# BL602 register map
Vendor: bouffalolab; Series: WiFi BT
Registers are 32-bit, read-write, reset 0x0 unless marked. A register's access mark holds for its fields unless they carry their own. Offsets are from the block's base; [hi:lo] are bit positions; {n}, {i} and the like mark numbered series.

## I2C — I2C control
Base 0x4000A300
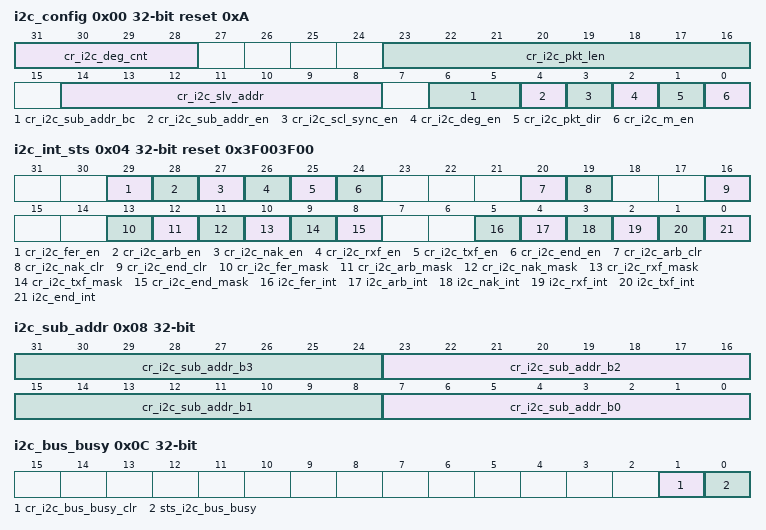
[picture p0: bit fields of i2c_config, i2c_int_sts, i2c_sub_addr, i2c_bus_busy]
0x00 i2c_config reset 0xA
  [31:28] cr_i2c_deg_cnt, [23:16] cr_i2c_pkt_len, [14:8] cr_i2c_slv_addr, [6:5] cr_i2c_sub_addr_bc, [4] cr_i2c_sub_addr_en, [3] cr_i2c_scl_sync_en, [2] cr_i2c_deg_en, [1] cr_i2c_pkt_dir, [0] cr_i2c_m_en
0x04 i2c_int_sts reset 0x3F003F00
  [29] cr_i2c_fer_en, [28] cr_i2c_arb_en, [27] cr_i2c_nak_en, [26] cr_i2c_rxf_en, [25] cr_i2c_txf_en, [24] cr_i2c_end_en, [20] cr_i2c_arb_clr, [19] cr_i2c_nak_clr, [16] cr_i2c_end_clr, [13] cr_i2c_fer_mask, [12] cr_i2c_arb_mask, [11] cr_i2c_nak_mask, [10] cr_i2c_rxf_mask, [9] cr_i2c_txf_mask, [8] cr_i2c_end_mask, [5] i2c_fer_int ro, [4] i2c_arb_int ro, [3] i2c_nak_int ro, [2] i2c_rxf_int ro, [1] i2c_txf_int ro, [0] i2c_end_int ro
0x08 i2c_sub_addr
  [8n+7:8n] cr_i2c_sub_addr_b{n} (n=0..3)
0x0C i2c_bus_busy
  [1] cr_i2c_bus_busy_clr, [0] sts_i2c_bus_busy ro
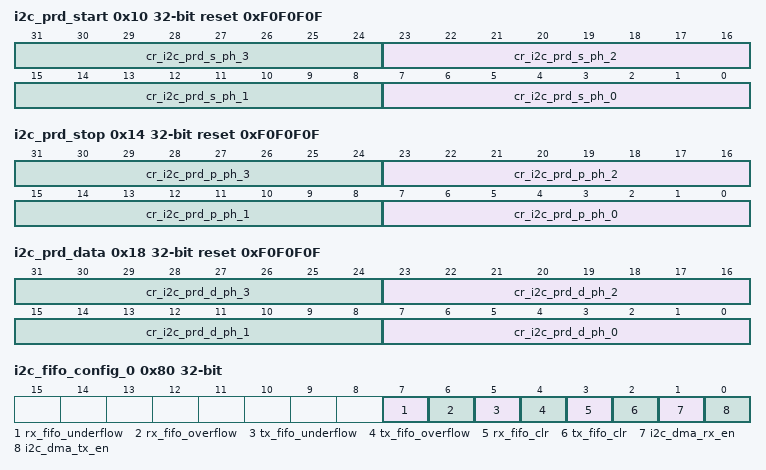
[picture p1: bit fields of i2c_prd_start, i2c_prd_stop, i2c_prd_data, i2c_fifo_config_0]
0x10 i2c_prd_start reset 0xF0F0F0F
  [8n+7:8n] cr_i2c_prd_s_ph_{n} (n=0..3)
0x14 i2c_prd_stop reset 0xF0F0F0F
  [8n+7:8n] cr_i2c_prd_p_ph_{n} (n=0..3)
0x18 i2c_prd_data reset 0xF0F0F0F
  [8n+7:8n] cr_i2c_prd_d_ph_{n} (n=0..3)
0x80 i2c_fifo_config_0
  [7] rx_fifo_underflow ro, [6] rx_fifo_overflow ro, [5] tx_fifo_underflow ro, [4] tx_fifo_overflow ro, [3] rx_fifo_clr, [2] tx_fifo_clr, [1] i2c_dma_rx_en, [0] i2c_dma_tx_en
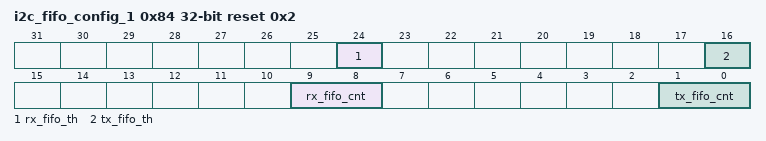
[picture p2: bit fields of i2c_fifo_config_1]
0x84 i2c_fifo_config_1 reset 0x2
  [24] rx_fifo_th, [16] tx_fifo_th, [9:8] rx_fifo_cnt ro, [1:0] tx_fifo_cnt ro
0x88 i2c_fifo_wdata wo
0x8C i2c_fifo_rdata ro

## PWM — Pulse width modulation control
Base 0x4000A400
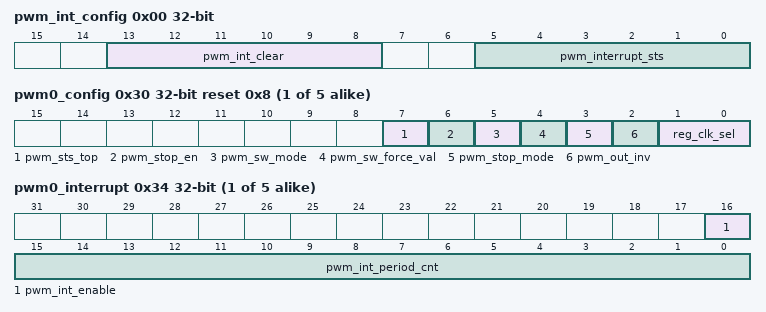
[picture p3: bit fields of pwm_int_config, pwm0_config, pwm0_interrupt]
0x00 pwm_int_config
  [13:8] pwm_int_clear wo, [5:0] pwm_interrupt_sts ro
{0x20+0x20*i} pwm{i}_clkdiv (i=0..4)
  [15:0] pwm_clk_div
{0x24+0x20*i} pwm{i}_thre1 (i=0..4)
  [15:0] pwm_thre1
{0x28+0x20*i} pwm{i}_thre2 (i=0..4)
  [15:0] pwm_thre2
{0x2C+0x20*i} pwm{i}_period (i=0..4)
  [15:0] pwm_period
{0x30+0x20*i} pwm{i}_config reset 0x8 (i=0..4)
  [7] pwm_sts_top ro, [6] pwm_stop_en, [5] pwm_sw_mode, [4] pwm_sw_force_val, [3] pwm_stop_mode, [2] pwm_out_inv, [1:0] reg_clk_sel
{0x34+0x20*i} pwm{i}_interrupt (i=0..4)
  [16] pwm_int_enable, [15:0] pwm_int_period_cnt

## TIMER — Timer control
Base 0x4000A500
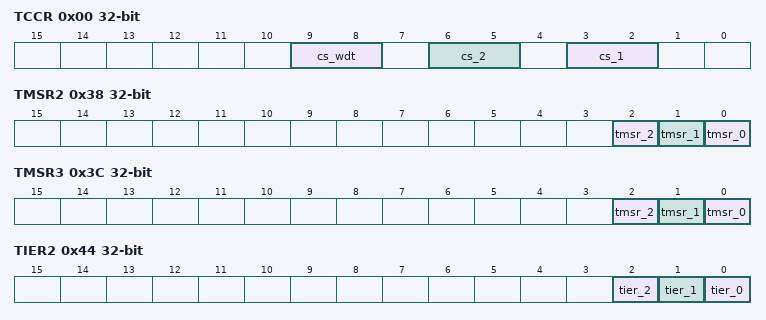
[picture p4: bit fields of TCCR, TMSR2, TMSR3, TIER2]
0x00 TCCR
  [9:8] cs_wdt, [6:5] cs_2, [3:2] cs_1
{0x10+4i} TMR2_{i} reset 0xFFFFFFFF (i=0..2)
  [31:0] tmr
{0x1C+4i} TMR3_{i} reset 0xFFFFFFFF (i=0..2)
  [31:0] tmr
0x2C TCR2 ro
  [31:0] tcr
0x30 TCR3 ro
  [31:0] tcr3_counter
0x38 TMSR2 ro
  [2] tmsr_2, [1] tmsr_1, [0] tmsr_0
0x3C TMSR3 ro
  [2] tmsr_2, [1] tmsr_1, [0] tmsr_0
0x44 TIER2
  [2] tier_2, [1] tier_1, [0] tier_0
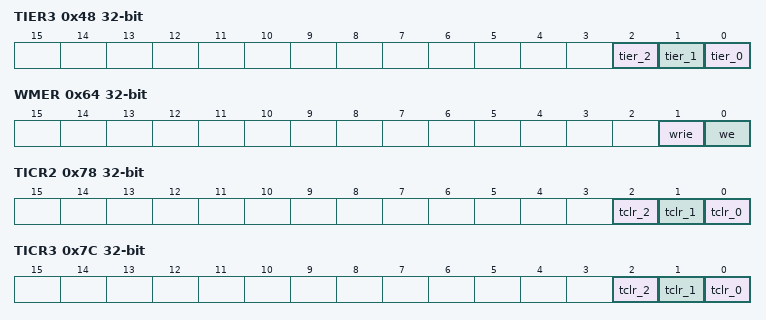
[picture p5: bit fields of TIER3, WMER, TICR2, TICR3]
0x48 TIER3
  [2] tier_2, [1] tier_1, [0] tier_0
0x50 TPLVR2
  [31:0] tplvr
0x54 TPLVR3
  [31:0] tplvr
0x5C TPLCR2
  [1:0] tplcr
0x60 TPLCR3
  [1:0] tplcr
0x64 WMER
  [1] wrie, [0] we
0x68 WMR reset 0xFFFF
  [15:0] wmr
0x6C WVR ro
  [15:0] wvr
0x70 WSR
  [0] wts
0x78 TICR2 wo
  [2] tclr_2, [1] tclr_1, [0] tclr_0
0x7C TICR3 wo
  [2] tclr_2, [1] tclr_1, [0] tclr_0
0x80 WICR wo
  [0] wiclr
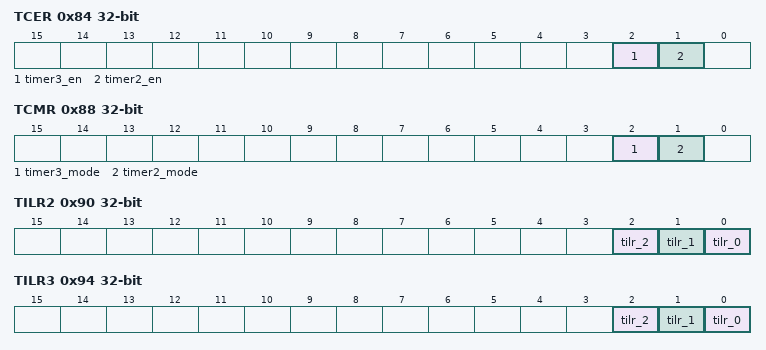
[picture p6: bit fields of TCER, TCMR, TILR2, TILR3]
0x84 TCER
  [2] timer3_en, [1] timer2_en
0x88 TCMR
  [2] timer3_mode, [1] timer2_mode
0x90 TILR2
  [2] tilr_2, [1] tilr_1, [0] tilr_0
0x94 TILR3
  [2] tilr_2, [1] tilr_1, [0] tilr_0
0x98 WCR wo
  [0] wcr
0x9C WFAR wo
  [15:0] wfar
0xA0 WSAR wo
  [15:0] wsar
0xA8 TCVWR2 ro
  [31:0] tcvwr
0xAC TCVWR3 ro
  [31:0] tcvwr
0xB4 TCVSYN2 ro
0xB8 TCVSYN3 ro
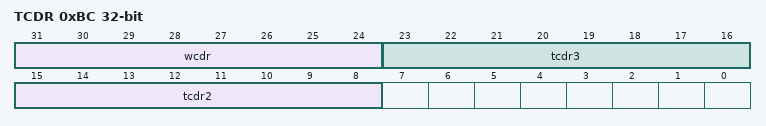
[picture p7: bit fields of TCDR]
0xBC TCDR
  [31:24] wcdr, [23:16] tcdr3, [15:8] tcdr2

## IR — Infrared remote control
Base 0x4000A600
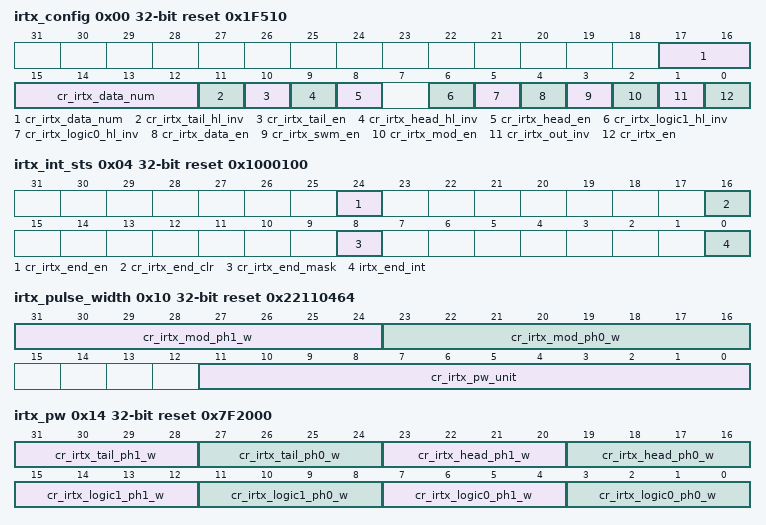
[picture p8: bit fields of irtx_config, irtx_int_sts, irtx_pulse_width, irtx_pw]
0x00 irtx_config reset 0x1F510
  [17:12] cr_irtx_data_num, [11] cr_irtx_tail_hl_inv, [10] cr_irtx_tail_en, [9] cr_irtx_head_hl_inv, [8] cr_irtx_head_en, [6] cr_irtx_logic1_hl_inv, [5] cr_irtx_logic0_hl_inv, [4] cr_irtx_data_en, [3] cr_irtx_swm_en, [2] cr_irtx_mod_en, [1] cr_irtx_out_inv, [0] cr_irtx_en
0x04 irtx_int_sts reset 0x1000100
  [24] cr_irtx_end_en, [16] cr_irtx_end_clr, [8] cr_irtx_end_mask, [0] irtx_end_int ro
0x08 irtx_data_word0
  [31:0] cr_irtx_data_word0
0x0C irtx_data_word1
  [31:0] cr_irtx_data_word1
0x10 irtx_pulse_width reset 0x22110464
  [31:24] cr_irtx_mod_ph1_w, [23:16] cr_irtx_mod_ph0_w, [11:0] cr_irtx_pw_unit
0x14 irtx_pw reset 0x7F2000
  [31:28] cr_irtx_tail_ph1_w, [27:24] cr_irtx_tail_ph0_w, [23:20] cr_irtx_head_ph1_w, [19:16] cr_irtx_head_ph0_w, [15:12] cr_irtx_logic1_ph1_w, [11:8] cr_irtx_logic1_ph0_w, [7:4] cr_irtx_logic0_ph1_w, [3:0] cr_irtx_logic0_ph0_w
{0x40+4i} irtx_swm_pw_{i} (i=0..7)
  [31:0] cr_irtx_swm_pw_{i}
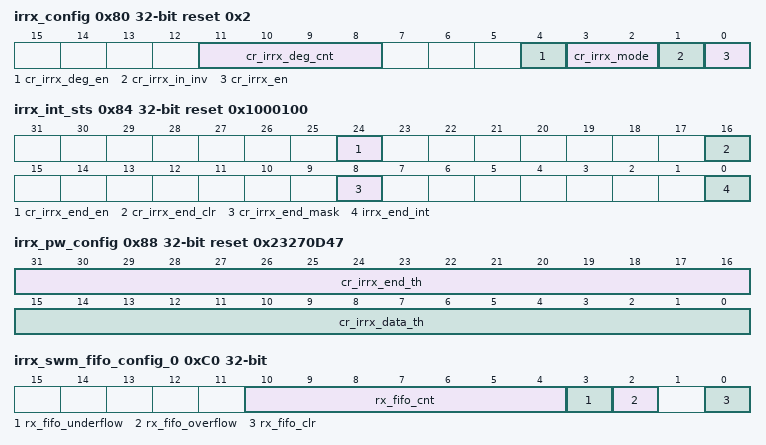
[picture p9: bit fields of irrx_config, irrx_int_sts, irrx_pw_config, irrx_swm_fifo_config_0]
0x80 irrx_config reset 0x2
  [11:8] cr_irrx_deg_cnt, [4] cr_irrx_deg_en, [3:2] cr_irrx_mode, [1] cr_irrx_in_inv, [0] cr_irrx_en
0x84 irrx_int_sts reset 0x1000100
  [24] cr_irrx_end_en, [16] cr_irrx_end_clr, [8] cr_irrx_end_mask, [0] irrx_end_int ro
0x88 irrx_pw_config reset 0x23270D47
  [31:16] cr_irrx_end_th, [15:0] cr_irrx_data_th
0x90 irrx_data_count
  [6:0] sts_irrx_data_cnt ro
0x94 irrx_data_word0
  [31:0] sts_irrx_data_word0 ro
0x98 irrx_data_word1
  [31:0] sts_irrx_data_word1 ro
0xC0 irrx_swm_fifo_config_0
  [10:4] rx_fifo_cnt ro, [3] rx_fifo_underflow ro, [2] rx_fifo_overflow ro, [0] rx_fifo_clr
0xC4 irrx_swm_fifo_rdata ro
  [15:0] rx_fifo_rdata
